AUTOSAR XML (schema 4-2-2)
package /ASW_Components
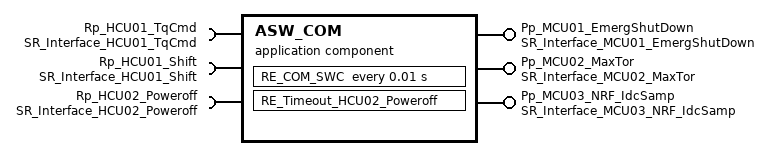
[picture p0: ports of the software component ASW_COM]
  application sw component type ASW_COM
    provide port Pp_MCU01_EmergShutDown: provided-interface=SR_Interface_MCU01_EmergShutDown
    provide port Pp_MCU02_MaxTor: provided-interface=SR_Interface_MCU02_MaxTor
    provide port Pp_MCU03_NRF_IdcSamp: provided-interface=SR_Interface_MCU03_NRF_IdcSamp
    require port Rp_HCU01_TqCmd: required-interface=SR_Interface_HCU01_TqCmd
    require port Rp_HCU01_Shift: required-interface=SR_Interface_HCU01_Shift
    require port Rp_HCU02_Poweroff: required-interface=SR_Interface_HCU02_Poweroff
    behavior IB_ASW_COM
      timing event TE_RE_COM_SWC_10ms: start-on-event=RE_COM_SWC, period=0.01
      data receive error event DREE_Rp_HCU02_Poweroff_Timeout: start-on-event=RE_Timeout_HCU02_Poweroff, data=Rp_HCU02_Poweroff.DE_Poweroff
      runnable RE_COM_SWC
        data-read-access:
          access VA_Read_TqCmd: accessed-variable=Rp_HCU01_TqCmd.DE_TqCmd
          access VA_Read_Shift: accessed-variable=Rp_HCU01_Shift.DE_Shift
          access VA_Read_Poweroff: accessed-variable=Rp_HCU02_Poweroff.DE_Poweroff
        data-write-access:
          access VA_Write_EmergShutDown: accessed-variable=Pp_MCU01_EmergShutDown.DE_EmergShutDown
          access VA_Write_MaxTor: accessed-variable=Pp_MCU02_MaxTor.DE_MaxTor
          access VA_Write_NRF_IdcSamp: accessed-variable=Pp_MCU03_NRF_IdcSamp.DE_NRF_IdcSamp
      runnable RE_Timeout_HCU02_Poweroff
package /COM_Interface
  6 x sender receiver interface:
    SR_Interface_HCU01_Shift
      data DE_Shift: type=Idt_uint8
    SR_Interface_HCU01_TqCmd
      data DE_TqCmd: type=Idt_sint16
    SR_Interface_HCU02_Poweroff
      data DE_Poweroff: type=Idt_boolean
    SR_Interface_MCU01_EmergShutDown
      data DE_EmergShutDown: type=Idt_boolean
    SR_Interface_MCU02_MaxTor
      data DE_MaxTor: type=Idt_sint16
    SR_Interface_MCU03_NRF_IdcSamp
      data DE_NRF_IdcSamp: type=Idt_uint16
package /DataTypes
  4 x impl type, all with category=VALUE:
    Idt_boolean: base-type=boolean
    Idt_sint16: base-type=sint16
    Idt_uint16: base-type=uint16
    Idt_uint8: base-type=uint8
